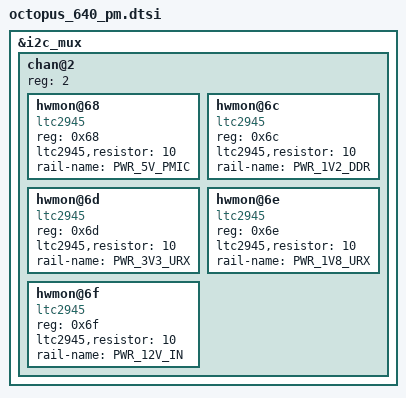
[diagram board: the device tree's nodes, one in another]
// SPDX-License-Identifier: GPL-2.0
/*
 * Copyright (C) 2024 MaxLinear, Inc.
 */

&i2c_mux {
	status = "okay";

	chan@2 {
		#address-cells = <1>;
		#size-cells = <0>;
		reg = <2>;

		hwmon@68 {
			compatible = "ltc2945";
			reg = <0x68>;
			ltc2945,resistor = <10>; /* the unit is mohm */
			rail-name = "PWR_5V_PMIC";
		};
		hwmon@6c {
			compatible = "ltc2945";
			reg = <0x6c>;
			ltc2945,resistor = <10>; /* the unit is mohm */
			rail-name = "PWR_1V2_DDR";
		};
		hwmon@6d {
			compatible = "ltc2945";
			reg = <0x6d>;
			ltc2945,resistor = <10>; /* the unit is mohm */
			rail-name = "PWR_3V3_URX";
		};
		hwmon@6e {
			compatible = "ltc2945";
			reg = <0x6e>;
			ltc2945,resistor = <10>; /* the unit is mohm */
			rail-name = "PWR_1V8_URX";
		};
		hwmon@6f {
			compatible = "ltc2945";
			reg = <0x6f>;
			ltc2945,resistor = <10>; /* the unit is mohm */
			rail-name = "PWR_12V_IN ";
		};
	};
};
